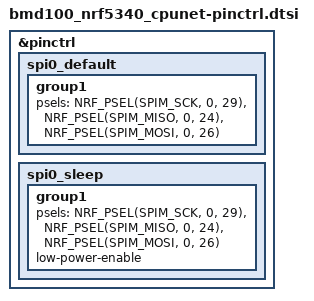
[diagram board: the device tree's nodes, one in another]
/*
 * Copyright (c) 2022 Nordic Semiconductor
 * SPDX-License-Identifier: Apache-2.0
 */

&pinctrl {
	spi0_default: spi0_default {
		group1 {
			psels = <NRF_PSEL(SPIM_SCK, 0, 29)>,
				<NRF_PSEL(SPIM_MISO, 0, 24)>,
				<NRF_PSEL(SPIM_MOSI, 0, 26)>;
		};
	};

	spi0_sleep: spi0_sleep {
		group1 {
			psels = <NRF_PSEL(SPIM_SCK, 0, 29)>,
				<NRF_PSEL(SPIM_MISO, 0, 24)>,
				<NRF_PSEL(SPIM_MOSI, 0, 26)>;
			low-power-enable;
		};
	};
};
